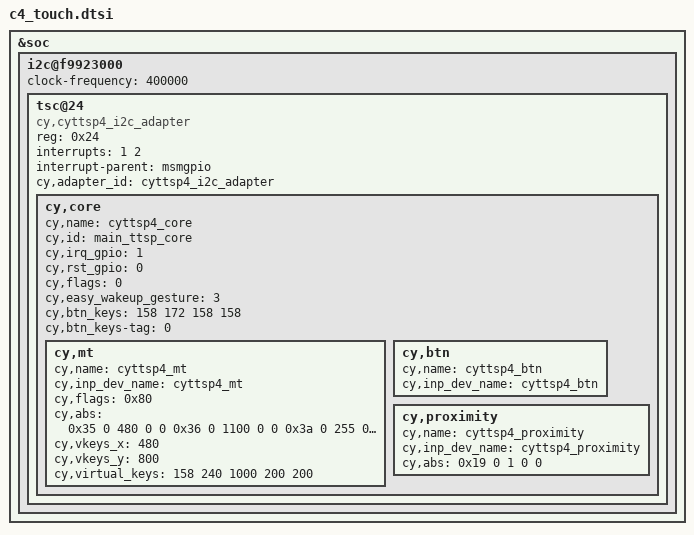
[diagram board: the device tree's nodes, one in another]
&soc {
    i2c@f9923000{
        clock-frequency = <400000>;

        tsc@24 {
                compatible = "cy,cyttsp4_i2c_adapter";
                reg = <0x24>;
                /* GPIO 38, high-to-low edge triggered */
                interrupts = <1 2>;
                /* JK CHECKTHIS */
                interrupt-parent = <&msmgpio>;
                cy,adapter_id = "cyttsp4_i2c_adapter";

                cy,core {

                        cy,name = "cyttsp4_core";
                        cy,id = "main_ttsp_core";

                        cy,irq_gpio = <1>;  /* was 38 */
                        cy,rst_gpio = <0>; /* was 37 */

                        cy,flags = <0>;

                        cy,easy_wakeup_gesture = <3>;
                        cy,btn_keys = <158     /* KEY_BACK */
                                       172     /* KEY_HOMEPAGE */
                                       158     /* KEY_BACK */
                                       158>;   /* KEY_BACK */

                        cy,btn_keys-tag = <0>;

                        cy,mt {
                                cy,name = "cyttsp4_mt";

                                cy,inp_dev_name = "cyttsp4_mt";
                                /* CY_MT_FLAG_FLIP | CY_MT_FLAG_INV_X | CY_MT_FLAG_INV_Y */
                                cy,flags = <0x80>;
                                cy,abs =
                                        /* ABS_MT_POSITION_X, CY_ABS_MIN_X, CY_ABS_MAX_X, 0, 0 */
                                        <0x35 0 480 0 0
                                        /* ABS_MT_POSITION_Y, CY_ABS_MIN_Y, CY_ABS_MAX_Y, 0, 0 */
                                        0x36 0 1100 0 0
                                        /* ABS_MT_PRESSURE, CY_ABS_MIN_P, CY_ABS_MAX_P, 0, 0 */
                                        0x3a 0 255 0 0
                                        /* CY_IGNORE_VALUE, CY_ABS_MIN_W, CY_ABS_MAX_W, 0, 0 */
                                        0xffff 0 255 0 0
                                        /* ABS_MT_TRACKING_ID, CY_ABS_MIN_T, CY_ABS_MAX_T, 0, 0 */
                                        0x39 0 32 0 0
                                        /* ABS_MT_TOUCH_MAJOR, 0, 255, 0, 0 */
                                        0x30 0 255 0 0
                                        /* ABS_MT_TOUCH_MINOR, 0, 255, 0, 0 */
                                        0x31 0 255 0 0
                                        /* ABS_MT_ORIENTATION, -128, 127, 0, 0 */
                                        0x34 0xfffffed7 127 0 0>;

                                cy,vkeys_x = <480>;
                                cy,vkeys_y = <800>;

                                cy,virtual_keys = /* KeyCode CenterX CenterY Width Height */
                                        /* KEY_BACK */
                                        <158 240 1000 200 200>;
                        };

                        cy,btn {
                                cy,name = "cyttsp4_btn";

                                cy,inp_dev_name = "cyttsp4_btn";
                        };

                        cy,proximity {
                                cy,name = "cyttsp4_proximity";

                                cy,inp_dev_name = "cyttsp4_proximity";
                                cy,abs =
                                        /* ABS_DISTANCE, CY_PROXIMITY_MIN_VAL, CY_PROXIMITY_MAX_VAL, 0, 0 */
                                        <0x19 0 1 0 0>;
                        };
                };


         };

    };
};
